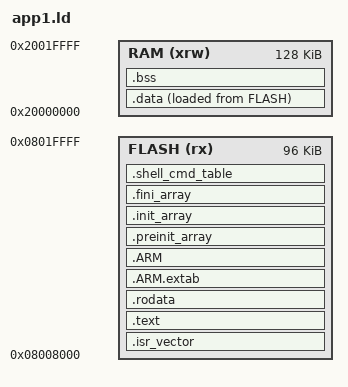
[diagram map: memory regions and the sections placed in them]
ENTRY(Reset_Handler)

_Min_Stack_Size = 0x1000;

MEMORY
{
    FLASH (rx)  : ORIGIN = 0x08008000, LENGTH = 0x00018000
    RAM   (xrw) : ORIGIN = 0x20000000, LENGTH = 0x00020000
}

/* Keep MSP inside RAM, not exactly at the exclusive upper bound.
 * Some bootloaders validate app vectors with sp < RAM_END.
 */
_estack = ORIGIN(RAM) + LENGTH(RAM) - 8;

SECTIONS
{
    .isr_vector :
    {
        . = ALIGN(4);
        KEEP(*(.isr_vector))
        . = ALIGN(4);
    } > FLASH

    .text :
    {
        . = ALIGN(4);
        *(.text)
        *(.text*)
        *(.glue_7)
        *(.glue_7t)
        *(.eh_frame)
        KEEP(*(.init))
        KEEP(*(.fini))
        . = ALIGN(4);
        _etext = .;
    } > FLASH

    .rodata :
    {
        . = ALIGN(4);
        *(.rodata)
        *(.rodata*)
        . = ALIGN(4);
    } > FLASH

    .ARM.extab :
    {
        *(.ARM.extab* .gnu.linkonce.armextab.*)
    } > FLASH

    .ARM :
    {
        __exidx_start = .;
        *(.ARM.exidx*)
        __exidx_end = .;
    } > FLASH

    .preinit_array :
    {
        PROVIDE_HIDDEN (__preinit_array_start = .);
        KEEP(*(.preinit_array*))
        PROVIDE_HIDDEN (__preinit_array_end = .);
    } > FLASH

    .init_array :
    {
        PROVIDE_HIDDEN (__init_array_start = .);
        KEEP(*(SORT(.init_array.*)))
        KEEP(*(.init_array*))
        PROVIDE_HIDDEN (__init_array_end = .);
    } > FLASH

    .fini_array :
    {
        PROVIDE_HIDDEN (__fini_array_start = .);
        KEEP(*(SORT(.fini_array.*)))
        KEEP(*(.fini_array*))
        PROVIDE_HIDDEN (__fini_array_end = .);
    } > FLASH

    .shell_cmd_table :
    {
        . = ALIGN(4);
        KEEP(*(ShellCmd$$Table$$A))
        KEEP(*(ShellCmd$$Table$$M))
        KEEP(*(ShellCmd$$Table$$Z))
        . = ALIGN(4);
    } > FLASH

    _sidata = LOADADDR(.data);
    .data :
    {
        . = ALIGN(4);
        _sdata = .;
        *(.data)
        *(.data*)
        *(.RamFunc)
        *(.RamFunc*)
        . = ALIGN(4);
        _edata = .;
    } > RAM AT > FLASH

    .bss (NOLOAD) :
    {
        . = ALIGN(4);
        _sbss = .;
        *(.bss)
        *(.bss*)
        *(COMMON)
        . = ALIGN(4);
        _ebss = .;
    } > RAM

    . = ALIGN(8);
    end = .;
    _end = .;

    ASSERT(_ebss <= (_estack - _Min_Stack_Size), "RAM overflow: not enough room left for the MSP stack.")
}
